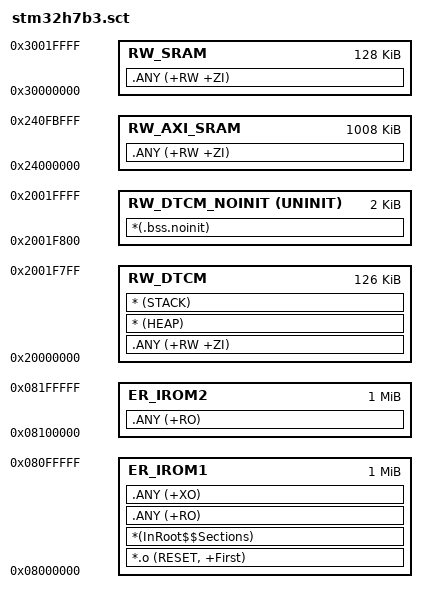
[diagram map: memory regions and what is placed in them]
; *************************************************************
; *** Scatter-Loading Description File generated by uVision ***
; *************************************************************

LR_IROM1 0x08000000 0x00100000  {      ; load region size_region
  ER_IROM1 0x08000000 0x00100000  {    ; load address = execution address
   *.o (RESET, +First)
   *(InRoot$$Sections)
   .ANY (+RO)
   .ANY (+XO)
  }
  RW_DTCM 0x20000000 0x0001F800  {
   .ANY (+RW +ZI)                      ; RW data
   * (HEAP)                            ; Heap
   * (STACK)                           ; Stack
  }
  RW_DTCM_NOINIT 0x2001F800 UNINIT 0x00000800  {
    *(.bss.noinit)
  }
  RW_AXI_SRAM 0x24000000 0x000FC000  { ; AXI RAM (16kB at the end (0x240FC000) is reserved for SDMMC1)
   .ANY (+RW +ZI)                      ; RW data
  }
  RW_SRAM 0x30000000 0x00020000  {     ; SRAM1 + SRAM2
   .ANY (+RW +ZI)                      ; RW data
  }
}

LR_IROM2 0x08100000 0x00100000  {
  ER_IROM2 0x08100000 0x00100000  {    ; load address = execution address
   .ANY (+RO)
  }
}
